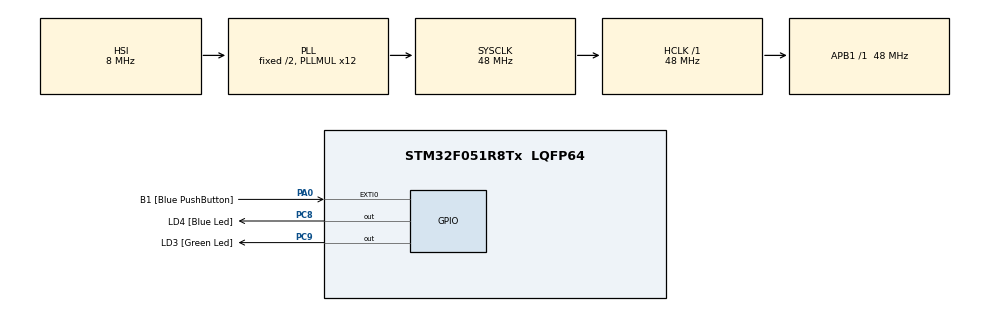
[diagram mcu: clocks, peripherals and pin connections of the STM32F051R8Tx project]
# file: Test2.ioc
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FREERTOS.BinarySemaphores01=mutex,Dynamic,NULL;phil0sem,Dynamic,NULL;phil1sem,Dynamic,NULL
FREERTOS.Tasks01=defaultTask,-3,64,StartDefaultTask,Default,NULL,Dynamic,NULL,NULL;Philosopher0,0,64,philosopher,Default,arr[0],Dynamic,NULL,NULL;Philosopher1,0,64,philosopher,Default,arr[1],Dynamic,NULL,NULL;Philosopher2,0,64,philosopher,Default,arr[2],Dynamic,NULL,NULL;Philosopher3,0,64,philosopher,Default,arr[3],Dynamic,NULL,NULL;Philosopher4,0,64,philosopher,Default,arr[4],Dynamic,NULL,NULL
FREERTOS.configMINIMAL_STACK_SIZE=64
FREERTOS.configUSE_MALLOC_FAILED_HOOK=1
Mcu.Family=STM32F0
Mcu.Name=STM32F051R8Tx
Mcu.Package=LQFP64
PA0.GPIO_Label=B1 [Blue PushButton]
PA0.GPIO_ModeDefaultEXTI=GPIO_MODE_EVT_RISING
PA0.Signal=GPXTI0
PA13.GPIO_Label=SWDIO
PA13.Mode=Serial_Wire
PA13.Signal=SYS_SWDIO
PA14.GPIO_Label=SWCLK
PA14.Mode=Serial_Wire
PA14.Signal=SYS_SWCLK
PC8.GPIO_Label=LD4 [Blue Led]
PC8.Signal=GPIO_Output
PC9.GPIO_Label=LD3 [Green Led]
PC9.Signal=GPIO_Output
ProjectManager.HeapSize=0x200
ProjectManager.StackSize=0x400
ProjectManager.TargetToolchain=STM32CubeIDE
RCC.AHBFreq_Value=48000000
RCC.APB1Freq_Value=48000000
RCC.APB1TimFreq_Value=48000000
RCC.HCLKFreq_Value=48000000
RCC.PLLMUL=RCC_PLL_MUL12
RCC.SYSCLKFreq_VALUE=48000000
RCC.SYSCLKSource=RCC_SYSCLKSOURCE_PLLCLK
VP_FREERTOS_VS_CMSIS_V1.Mode=CMSIS_V1
board=STM32F0DISCOVERY

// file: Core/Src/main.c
/* USER CODE BEGIN Header */
/**
  ******************************************************************************
  * @file           : main.c
  * @brief          : Main program body
  ******************************************************************************
  * @attention
  *
  * Copyright (c) 2022 STMicroelectronics.
  * All rights reserved.
  *
  * This software is licensed under terms that can be found in the LICENSE file
  * in the root directory of this software component.
  * If no LICENSE file comes with this software, it is provided AS-IS.
  *
  ******************************************************************************
  */
/* USER CODE END Header */
#include "main.h"
#include "cmsis_os.h"
#include "philosopher_interface.h"

 osThreadId defaultTaskHandle;
osThreadId Philosopher0Handle;
osThreadId Philosopher1Handle;
osThreadId Philosopher2Handle;
osThreadId Philosopher3Handle;
osThreadId Philosopher4Handle;
osSemaphoreId mutexHandle;
osSemaphoreId phil0semHandle;
osSemaphoreId phil1semHandle;
osSemaphoreId phil2semHandle;
osSemaphoreId phil3semHandle;
osSemaphoreId phil4semHandle;
osSemaphoreId phil_sem_arr[5];

void SystemClock_Config(void);
static void MX_GPIO_Init(void);
void StartDefaultTask(void const * argument);
void philosopher(uint8_t argument);
void take_forks(uint8_t argument, uint8_t* state);
void test(uint8_t argument, uint8_t* state);

int main(void)
{

  /* MCU Configuration--------------------------------------------------------*/

  /* Reset of all peripherals, Initializes the Flash interface and the Systick. */
  HAL_Init();

  /* Configure the system clock */
  SystemClock_Config();

  /* Initialize all configured peripherals */
  MX_GPIO_Init();

  /* Create the semaphores(s) */
  /* definition and creation of mutex */
  osSemaphoreDef(mutex);
  mutexHandle = osSemaphoreCreate(osSemaphore(mutex), 1);

  /* definition and creation of phil0sem */
  osSemaphoreDef(phil0sem);
  phil0semHandle = osSemaphoreCreate(osSemaphore(phil0sem), 1);
  phil_sem_arr[0] = phil0semHandle;
  vQueueAddToRegistry(phil0semHandle, "Phil0Semaphore");
  /* definition and creation of phil1sem */
  osSemaphoreDef(phil1sem);
  phil1semHandle = osSemaphoreCreate(osSemaphore(phil1sem), 1);
  phil_sem_arr[1] = phil1semHandle;
  vQueueAddToRegistry(phil1semHandle, "Phil1Semaphore");
  /* definition and creation of phil2sem */
  osSemaphoreDef(phil2sem);
  phil2semHandle = osSemaphoreCreate(osSemaphore(phil2sem), 1);
  phil_sem_arr[2] = phil2semHandle;
  vQueueAddToRegistry(phil2semHandle, "Phil2Semaphore");
  /* definition and creation of phil3sem */
  osSemaphoreDef(phil3sem);
  phil3semHandle = osSemaphoreCreate(osSemaphore(phil3sem), 1);
  phil_sem_arr[3] = phil3semHandle;
  vQueueAddToRegistry(phil3semHandle, "Phil3Semaphore");
  /* definition and creation of phil4sem */
  osSemaphoreDef(phil4sem);
  phil4semHandle = osSemaphoreCreate(osSemaphore(phil4sem), 1);
  phil_sem_arr[4] = phil4semHandle;
  vQueueAddToRegistry(phil4semHandle, "Phil4Semaphore");

  /* Create the thread(s) */
  /* definition and creation of defaultTask */
  osThreadDef(defaultTask, StartDefaultTask, osPriorityNormal, 0, 64);
  defaultTaskHandle = osThreadCreate(osThread(defaultTask), NULL);

  /* definition and creation of Philosopher0 */
  osThreadDef(Philosopher0, philosopher, osPriorityNormal, 0, 64);
  Philosopher0Handle = osThreadCreate(osThread(Philosopher0), 0);

  /* definition and creation of Philosopher1 */
  osThreadDef(Philosopher1, philosopher, osPriorityNormal, 0, 64);
  Philosopher1Handle = osThreadCreate(osThread(Philosopher1), 1);

  /* definition and creation of Philosopher2 */
  osThreadDef(Philosopher2, philosopher, osPriorityNormal, 0, 64);
  Philosopher2Handle = osThreadCreate(osThread(Philosopher2), 2);

  /* definition and creation of Philosopher3 */
  osThreadDef(Philosopher3, philosopher, osPriorityNormal, 0, 64);
  Philosopher3Handle = osThreadCreate(osThread(Philosopher3), 3);

  /* definition and creation of Philosopher4 */
  osThreadDef(Philosopher4, philosopher, osPriorityNormal, 0, 64);
  Philosopher4Handle = osThreadCreate(osThread(Philosopher4), 4);

  /* Start scheduler */
  osKernelStart();

  /* We should never get here as control is now taken by the scheduler */
  /* Infinite loop */
  while (1)
  {

  }
}

void SystemClock_Config(void)
{
  RCC_OscInitTypeDef RCC_OscInitStruct = {0};
  RCC_ClkInitTypeDef RCC_ClkInitStruct = {0};

  /** Initializes the RCC Oscillators according to the specified parameters
  * in the RCC_OscInitTypeDef structure.
  */
  RCC_OscInitStruct.OscillatorType = RCC_OSCILLATORTYPE_HSI;
  RCC_OscInitStruct.HSIState = RCC_HSI_ON;
  RCC_OscInitStruct.HSICalibrationValue = RCC_HSICALIBRATION_DEFAULT;
  RCC_OscInitStruct.PLL.PLLState = RCC_PLL_ON;
  RCC_OscInitStruct.PLL.PLLSource = RCC_PLLSOURCE_HSI;
  RCC_OscInitStruct.PLL.PLLMUL = RCC_PLL_MUL12;
  RCC_OscInitStruct.PLL.PREDIV = RCC_PREDIV_DIV1;
  if (HAL_RCC_OscConfig(&RCC_OscInitStruct) != HAL_OK)
  {
    Error_Handler();
  }

  /** Initializes the CPU, AHB and APB buses clocks
  */
  RCC_ClkInitStruct.ClockType = RCC_CLOCKTYPE_HCLK|RCC_CLOCKTYPE_SYSCLK
                              |RCC_CLOCKTYPE_PCLK1;
  RCC_ClkInitStruct.SYSCLKSource = RCC_SYSCLKSOURCE_PLLCLK;
  RCC_ClkInitStruct.AHBCLKDivider = RCC_SYSCLK_DIV1;
  RCC_ClkInitStruct.APB1CLKDivider = RCC_HCLK_DIV1;

  if (HAL_RCC_ClockConfig(&RCC_ClkInitStruct, FLASH_LATENCY_1) != HAL_OK)
  {
    Error_Handler();
  }
}

static void MX_GPIO_Init(void)
{
  GPIO_InitTypeDef GPIO_InitStruct = {0};

  /* GPIO Ports Clock Enable */
  __HAL_RCC_GPIOA_CLK_ENABLE();
  __HAL_RCC_GPIOC_CLK_ENABLE();

  /*Configure GPIO pin Output Level */
  HAL_GPIO_WritePin(GPIOC, LD4_Pin|LD3_Pin, GPIO_PIN_RESET);

  /*Configure GPIO pin : B1_Pin */
  GPIO_InitStruct.Pin = B1_Pin;
  GPIO_InitStruct.Mode = GPIO_MODE_EVT_RISING;
  GPIO_InitStruct.Pull = GPIO_NOPULL;
  HAL_GPIO_Init(B1_GPIO_Port, &GPIO_InitStruct);

  /*Configure GPIO pins : LD4_Pin LD3_Pin */
  GPIO_InitStruct.Pin = LD4_Pin|LD3_Pin;
  GPIO_InitStruct.Mode = GPIO_MODE_OUTPUT_PP;
  GPIO_InitStruct.Pull = GPIO_NOPULL;
  GPIO_InitStruct.Speed = GPIO_SPEED_FREQ_LOW;
  HAL_GPIO_Init(GPIOC, &GPIO_InitStruct);

}

void StartDefaultTask(void const * argument)
{
  /* USER CODE BEGIN 5 */
  /* Infinite loop */
	  for (int i=0; i<5; i++)
	  {
		  osSemaphoreWait(phil_sem_arr[i], 0);
	  }
  for(;;)
  {
    osDelay(0);
  }
  /* USER CODE END 5 */
}

void philosopher(uint8_t argument)
{
  /* USER CODE BEGIN philosopher */
  /* Infinite loop */
  static uint8_t state[5] = {0,0,0,0,0};

  for(;;)
  {
	take_forks(argument, state);
	osDelay(3); // EATING
	put_forks(argument, state);

  }
  /* USER CODE END philosopher */
}

void take_forks(uint8_t argument, uint8_t* state)
{
	osSemaphoreWait(mutexHandle, 0);
	{
			state[argument] = HUNGRY;
			test(argument, state);
	}
	osSemaphoreRelease(mutexHandle);
	osSemaphoreWait(phil_sem_arr[argument], 5);

}

void put_forks(uint8_t argument, uint8_t* state)
{
	osSemaphoreWait(mutexHandle, 0);
		{
				state[argument] = THINKING;
				test(LEFT, state);
				test(RIGHT, state);

		}
		osSemaphoreRelease(mutexHandle);

}

void test(uint8_t argument, uint8_t* state)
{
	if (state[argument] == HUNGRY && state[LEFT] != EATING && state[RIGHT] != EATING)
	{
		state[argument] = EATING;
		osSemaphoreRelease(phil_sem_arr[argument]);
	}
}

void Error_Handler(void)
{
  __disable_irq();
  while (1)
  {
  }
}

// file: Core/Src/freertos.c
/* USER CODE BEGIN Header */
/**
  ******************************************************************************
  * File Name          : freertos.c
  * Description        : Code for freertos applications
  ******************************************************************************
  * @attention
  *
  * Copyright (c) 2022 STMicroelectronics.
  * All rights reserved.
  *
  * This software is licensed under terms that can be found in the LICENSE file
  * in the root directory of this software component.
  * If no LICENSE file comes with this software, it is provided AS-IS.
  *
  ******************************************************************************
  */
/* USER CODE END Header */

#include "FreeRTOS.h"
#include "task.h"
#include "main.h"

/* GetIdleTaskMemory prototype (linked to static allocation support) */
void vApplicationGetIdleTaskMemory( StaticTask_t **ppxIdleTaskTCBBuffer, StackType_t **ppxIdleTaskStackBuffer, uint32_t *pulIdleTaskStackSize );

/* Hook prototypes */
void vApplicationMallocFailedHook(void);

/* USER CODE BEGIN 5 */
__weak void vApplicationMallocFailedHook(void)
{
   /* vApplicationMallocFailedHook() will only be called if
   configUSE_MALLOC_FAILED_HOOK is set to 1 in FreeRTOSConfig.h. It is a hook
   function that will get called if a call to pvPortMalloc() fails.
   pvPortMalloc() is called internally by the kernel whenever a task, queue,
   timer or semaphore is created. It is also called by various parts of the
   demo application. If heap_1.c or heap_2.c are used, then the size of the
   heap available to pvPortMalloc() is defined by configTOTAL_HEAP_SIZE in
   FreeRTOSConfig.h, and the xPortGetFreeHeapSize() API function can be used
   to query the size of free heap space that remains (although it does not
   provide information on how the remaining heap might be fragmented). */
}
/* USER CODE END 5 */

/* USER CODE BEGIN GET_IDLE_TASK_MEMORY */
static StaticTask_t xIdleTaskTCBBuffer;
static StackType_t xIdleStack[configMINIMAL_STACK_SIZE];

void vApplicationGetIdleTaskMemory( StaticTask_t **ppxIdleTaskTCBBuffer, StackType_t **ppxIdleTaskStackBuffer, uint32_t *pulIdleTaskStackSize )
{
  *ppxIdleTaskTCBBuffer = &xIdleTaskTCBBuffer;
  *ppxIdleTaskStackBuffer = &xIdleStack[0];
  *pulIdleTaskStackSize = configMINIMAL_STACK_SIZE;
  /* place for user code */
}
/* USER CODE END GET_IDLE_TASK_MEMORY */
